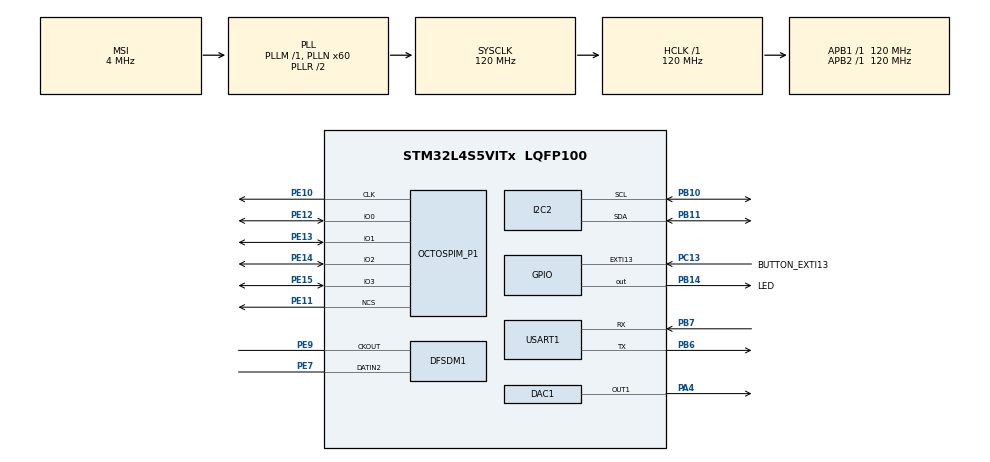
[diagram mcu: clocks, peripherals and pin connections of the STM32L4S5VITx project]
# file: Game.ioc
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DAC1.DAC_Trigger-DAC_OUT1=DAC_TRIGGER_T2_TRGO
DFSDM1.Divider=48
DFSDM1.DmaMode_reg_FIL0=ENABLE
DFSDM1.FastMode_reg_FIL0=ENABLE
DFSDM1.Filter_regChannel_FIL0=DFSDM_CHANNEL_2
DFSDM1.Fosr_FIL0=100
Dma.DAC1_CH1.0.Direction=DMA_MEMORY_TO_PERIPH
Dma.DAC1_CH1.0.EventEnable=DISABLE
Dma.DAC1_CH1.0.Instance=DMA1_Channel1
Dma.DAC1_CH1.0.MemDataAlignment=DMA_MDATAALIGN_WORD
Dma.DAC1_CH1.0.MemInc=DMA_MINC_ENABLE
Dma.DAC1_CH1.0.Mode=DMA_CIRCULAR
Dma.DAC1_CH1.0.PeriphDataAlignment=DMA_PDATAALIGN_WORD
Dma.DAC1_CH1.0.PeriphInc=DMA_PINC_DISABLE
Dma.DAC1_CH1.0.Polarity=HAL_DMAMUX_REQUEST_GEN_RISING
Dma.DAC1_CH1.0.Priority=DMA_PRIORITY_HIGH
Dma.DAC1_CH1.0.RequestNumber=1
Dma.DAC1_CH1.0.SignalID=NONE
Dma.DAC1_CH1.0.SyncEnable=DISABLE
Dma.DAC1_CH1.0.SyncPolarity=HAL_DMAMUX_SYNC_NO_EVENT
Dma.DAC1_CH1.0.SyncRequestNumber=1
Dma.DAC1_CH1.0.SyncSignalID=NONE
Dma.DFSDM1_FLT0.1.Direction=DMA_PERIPH_TO_MEMORY
Dma.DFSDM1_FLT0.1.EventEnable=DISABLE
Dma.DFSDM1_FLT0.1.Instance=DMA1_Channel2
Dma.DFSDM1_FLT0.1.MemDataAlignment=DMA_MDATAALIGN_WORD
Dma.DFSDM1_FLT0.1.MemInc=DMA_MINC_ENABLE
Dma.DFSDM1_FLT0.1.Mode=DMA_CIRCULAR
Dma.DFSDM1_FLT0.1.PeriphDataAlignment=DMA_PDATAALIGN_WORD
Dma.DFSDM1_FLT0.1.PeriphInc=DMA_PINC_DISABLE
Dma.DFSDM1_FLT0.1.Polarity=HAL_DMAMUX_REQUEST_GEN_RISING
Dma.DFSDM1_FLT0.1.Priority=DMA_PRIORITY_LOW
Dma.DFSDM1_FLT0.1.RequestNumber=1
Dma.DFSDM1_FLT0.1.SignalID=NONE
Dma.DFSDM1_FLT0.1.SyncEnable=DISABLE
Dma.DFSDM1_FLT0.1.SyncPolarity=HAL_DMAMUX_SYNC_NO_EVENT
Dma.DFSDM1_FLT0.1.SyncRequestNumber=1
Dma.DFSDM1_FLT0.1.SyncSignalID=NONE
Dma.Request0=DAC1_CH1
Dma.Request1=DFSDM1_FLT0
I2C2.Timing=0x30A175AB
Mcu.Family=STM32L4
Mcu.Name=STM32L4S5VITx
Mcu.Package=LQFP100
NVIC.DMA1_Channel1_IRQn=true\:0\:0\:false\:false\:true\:false\:true\:true
NVIC.DMA1_Channel2_IRQn=true\:0\:0\:false\:false\:true\:false\:true\:true
NVIC.EXTI15_10_IRQn=true\:0\:0\:false\:false\:true\:true\:true\:true
NVIC.PriorityGroup=NVIC_PRIORITYGROUP_4
NVIC.TIM2_IRQn=true\:0\:0\:false\:false\:true\:true\:true\:true
PA4.Signal=COMP_DAC11_group
PB10.Mode=I2C
PB10.Signal=I2C2_SCL
PB11.Mode=I2C
PB11.Signal=I2C2_SDA
PB14.GPIO_Label=LED
PB14.Signal=GPIO_Output
PB6.Mode=Asynchronous
PB6.Signal=USART1_TX
PB7.Mode=Asynchronous
PB7.Signal=USART1_RX
PC13.GPIO_Label=BUTTON_EXTI13
PC13.Signal=GPXTI13
PE10.Mode=O1_P1_CLK
PE10.Signal=OCTOSPIM_P1_CLK
PE11.Mode=OCTOSPI1_Port1_NCS
PE11.Signal=OCTOSPIM_P1_NCS
PE12.Mode=OCTOSPI1_IOL_Port1L
PE12.Signal=OCTOSPIM_P1_IO0
PE13.Mode=OCTOSPI1_IOL_Port1L
PE13.Signal=OCTOSPIM_P1_IO1
PE14.Mode=OCTOSPI1_IOL_Port1L
PE14.Signal=OCTOSPIM_P1_IO2
PE15.Mode=OCTOSPI1_IOL_Port1L
PE15.Signal=OCTOSPIM_P1_IO3
PE7.Signal=S_DATAIN2DFSDM1
PE9.Signal=S_CKOUTDFSDM1
ProjectManager.HeapSize=0x200
ProjectManager.StackSize=0x400
ProjectManager.TargetToolchain=STM32CubeIDE
RCC.ADCFreq_Value=48000000
RCC.AHBFreq_Value=120000000
RCC.APB1Freq_Value=120000000
RCC.APB1TimFreq_Value=120000000
RCC.APB2Freq_Value=120000000
RCC.APB2TimFreq_Value=120000000
RCC.CortexFreq_Value=120000000
RCC.HCLKFreq_Value=120000000
RCC.HSE_VALUE=8000000
RCC.HSI48_VALUE=48000000
RCC.HSI_VALUE=16000000
RCC.LSE_VALUE=32768
RCC.MSI_VALUE=4000000
RCC.PLLN=60
RCC.PLLSAI1N=24
RCC.SYSCLKFreq_VALUE=120000000
RCC.SYSCLKSource=RCC_SYSCLKSOURCE_PLLCLK
RCC.USBFreq_Value=48000000
RCC.VCOOutputFreq_Value=240000000
SH.COMP_DAC11_group.0=DAC1_OUT1,DAC_OUT1
SH.S_CKOUTDFSDM1.0=DFSDM1_CKOUT,CKOUT
SH.S_CKOUTDFSDM1.1=DFSDM1_CKOUT,PDM_SPI_input_from_ch2_and_internal_clock
SH.S_DATAIN2DFSDM1.0=DFSDM1_DATIN2,PDM_SPI_input_from_ch2_and_internal_clock
TIM2.Period=4800
TIM2.TIM_MasterOutputTrigger=TIM_TRGO_UPDATE
USART1.VirtualMode-Asynchronous=VM_ASYNC
VP_OCTOSPI1_VS_quad.Mode=quad_mode
VP_TIM2_VS_ClockSourceINT.Mode=Internal
board=B-L4S5I-IOT01A

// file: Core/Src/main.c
/* USER CODE BEGIN Header */
/**
  ******************************************************************************
  * @file           : main.c
  * @brief          : Main program body
  ******************************************************************************
  * @attention
  *
  * Copyright (c) 2025 STMicroelectronics.
  * All rights reserved.
  *
  * This software is licensed under terms that can be found in the LICENSE file
  * in the root directory of this software component.
  * If no LICENSE file comes with this software, it is provided AS-IS.
  *
  ******************************************************************************
  */
/* USER CODE END Header */
#include "main.h"

/* USER CODE BEGIN Includes */
#include "stm32l4s5i_iot01_qspi.h"
#include "app.h"
#include "audio_player.h"
/* USER CODE END Includes */

DAC_HandleTypeDef hdac1;
DMA_HandleTypeDef hdma_dac1_ch1;

DFSDM_Filter_HandleTypeDef hdfsdm1_filter0;
DFSDM_Channel_HandleTypeDef hdfsdm1_channel2;
DMA_HandleTypeDef hdma_dfsdm1_flt0;

I2C_HandleTypeDef hi2c2;

OSPI_HandleTypeDef hospi1;

TIM_HandleTypeDef htim2;

UART_HandleTypeDef huart1;

void SystemClock_Config(void);
static void MX_GPIO_Init(void);
static void MX_DMA_Init(void);
static void MX_DFSDM1_Init(void);
static void MX_USART1_UART_Init(void);
static void MX_I2C2_Init(void);
static void MX_OCTOSPI1_Init(void);
static void MX_TIM2_Init(void);
static void MX_DAC1_Init(void);

int main(void)
{

  /* MCU Configuration--------------------------------------------------------*/

  /* Reset of all peripherals, Initializes the Flash interface and the Systick. */
  HAL_Init();

  /* Configure the system clock */
  SystemClock_Config();

  /* Initialize all configured peripherals */
  MX_GPIO_Init();
  MX_DMA_Init();
  MX_DFSDM1_Init();
  MX_USART1_UART_Init();
  MX_I2C2_Init();
  MX_OCTOSPI1_Init();
  MX_TIM2_Init();
  MX_DAC1_Init();
  /* USER CODE BEGIN 2 */
  BOPIT_Set_I2C_Handle(&hi2c2);
  BOPIT_Set_UART_Handle(&huart1);
  if(BSP_QSPI_Init() != QSPI_OK){
	  Error_Handler();
  }
  HAL_TIM_Base_Start_IT(&htim2);
  AP_Init(&hdac1, &hdfsdm1_filter0);
  BOPIT_Start();

  /* USER CODE END 2 */

  /* Infinite loop */
  while (1)
  {

  }
}

void SystemClock_Config(void)
{
  RCC_OscInitTypeDef RCC_OscInitStruct = {0};
  RCC_ClkInitTypeDef RCC_ClkInitStruct = {0};

  /** Configure the main internal regulator output voltage
  */
  if (HAL_PWREx_ControlVoltageScaling(PWR_REGULATOR_VOLTAGE_SCALE1_BOOST) != HAL_OK)
  {
    Error_Handler();
  }

  /** Initializes the RCC Oscillators according to the specified parameters
  * in the RCC_OscInitTypeDef structure.
  */
  RCC_OscInitStruct.OscillatorType = RCC_OSCILLATORTYPE_MSI;
  RCC_OscInitStruct.MSIState = RCC_MSI_ON;
  RCC_OscInitStruct.MSICalibrationValue = 0;
  RCC_OscInitStruct.MSIClockRange = RCC_MSIRANGE_6;
  RCC_OscInitStruct.PLL.PLLState = RCC_PLL_ON;
  RCC_OscInitStruct.PLL.PLLSource = RCC_PLLSOURCE_MSI;
  RCC_OscInitStruct.PLL.PLLM = 1;
  RCC_OscInitStruct.PLL.PLLN = 60;
  RCC_OscInitStruct.PLL.PLLP = RCC_PLLP_DIV2;
  RCC_OscInitStruct.PLL.PLLQ = RCC_PLLQ_DIV2;
  RCC_OscInitStruct.PLL.PLLR = RCC_PLLR_DIV2;
  if (HAL_RCC_OscConfig(&RCC_OscInitStruct) != HAL_OK)
  {
    Error_Handler();
  }

  /** Initializes the CPU, AHB and APB buses clocks
  */
  RCC_ClkInitStruct.ClockType = RCC_CLOCKTYPE_HCLK|RCC_CLOCKTYPE_SYSCLK
                              |RCC_CLOCKTYPE_PCLK1|RCC_CLOCKTYPE_PCLK2;
  RCC_ClkInitStruct.SYSCLKSource = RCC_SYSCLKSOURCE_PLLCLK;
  RCC_ClkInitStruct.AHBCLKDivider = RCC_SYSCLK_DIV1;
  RCC_ClkInitStruct.APB1CLKDivider = RCC_HCLK_DIV1;
  RCC_ClkInitStruct.APB2CLKDivider = RCC_HCLK_DIV1;

  if (HAL_RCC_ClockConfig(&RCC_ClkInitStruct, FLASH_LATENCY_5) != HAL_OK)
  {
    Error_Handler();
  }
}

static void MX_DAC1_Init(void)
{

  DAC_ChannelConfTypeDef sConfig = {0};

  /** DAC Initialization
  */
  hdac1.Instance = DAC1;
  if (HAL_DAC_Init(&hdac1) != HAL_OK)
  {
    Error_Handler();
  }

  /** DAC channel OUT1 config
  */
  sConfig.DAC_SampleAndHold = DAC_SAMPLEANDHOLD_DISABLE;
  sConfig.DAC_Trigger = DAC_TRIGGER_T2_TRGO;
  sConfig.DAC_HighFrequency = DAC_HIGH_FREQUENCY_INTERFACE_MODE_ABOVE_80MHZ;
  sConfig.DAC_OutputBuffer = DAC_OUTPUTBUFFER_ENABLE;
  sConfig.DAC_ConnectOnChipPeripheral = DAC_CHIPCONNECT_DISABLE;
  sConfig.DAC_UserTrimming = DAC_TRIMMING_FACTORY;
  if (HAL_DAC_ConfigChannel(&hdac1, &sConfig, DAC_CHANNEL_1) != HAL_OK)
  {
    Error_Handler();
  }

}

static void MX_DFSDM1_Init(void)
{

  hdfsdm1_filter0.Instance = DFSDM1_Filter0;
  hdfsdm1_filter0.Init.RegularParam.Trigger = DFSDM_FILTER_SW_TRIGGER;
  hdfsdm1_filter0.Init.RegularParam.FastMode = ENABLE;
  hdfsdm1_filter0.Init.RegularParam.DmaMode = ENABLE;
  hdfsdm1_filter0.Init.FilterParam.SincOrder = DFSDM_FILTER_FASTSINC_ORDER;
  hdfsdm1_filter0.Init.FilterParam.Oversampling = 100;
  hdfsdm1_filter0.Init.FilterParam.IntOversampling = 1;
  if (HAL_DFSDM_FilterInit(&hdfsdm1_filter0) != HAL_OK)
  {
    Error_Handler();
  }
  hdfsdm1_channel2.Instance = DFSDM1_Channel2;
  hdfsdm1_channel2.Init.OutputClock.Activation = ENABLE;
  hdfsdm1_channel2.Init.OutputClock.Selection = DFSDM_CHANNEL_OUTPUT_CLOCK_SYSTEM;
  hdfsdm1_channel2.Init.OutputClock.Divider = 48;
  hdfsdm1_channel2.Init.Input.Multiplexer = DFSDM_CHANNEL_EXTERNAL_INPUTS;
  hdfsdm1_channel2.Init.Input.DataPacking = DFSDM_CHANNEL_STANDARD_MODE;
  hdfsdm1_channel2.Init.Input.Pins = DFSDM_CHANNEL_SAME_CHANNEL_PINS;
  hdfsdm1_channel2.Init.SerialInterface.Type = DFSDM_CHANNEL_SPI_RISING;
  hdfsdm1_channel2.Init.SerialInterface.SpiClock = DFSDM_CHANNEL_SPI_CLOCK_INTERNAL;
  hdfsdm1_channel2.Init.Awd.FilterOrder = DFSDM_CHANNEL_FASTSINC_ORDER;
  hdfsdm1_channel2.Init.Awd.Oversampling = 1;
  hdfsdm1_channel2.Init.Offset = 0;
  hdfsdm1_channel2.Init.RightBitShift = 0x00;
  if (HAL_DFSDM_ChannelInit(&hdfsdm1_channel2) != HAL_OK)
  {
    Error_Handler();
  }
  if (HAL_DFSDM_FilterConfigRegChannel(&hdfsdm1_filter0, DFSDM_CHANNEL_2, DFSDM_CONTINUOUS_CONV_ON) != HAL_OK)
  {
    Error_Handler();
  }

}

static void MX_I2C2_Init(void)
{

  hi2c2.Instance = I2C2;
  hi2c2.Init.Timing = 0x30A175AB;
  hi2c2.Init.OwnAddress1 = 0;
  hi2c2.Init.AddressingMode = I2C_ADDRESSINGMODE_7BIT;
  hi2c2.Init.DualAddressMode = I2C_DUALADDRESS_DISABLE;
  hi2c2.Init.OwnAddress2 = 0;
  hi2c2.Init.OwnAddress2Masks = I2C_OA2_NOMASK;
  hi2c2.Init.GeneralCallMode = I2C_GENERALCALL_DISABLE;
  hi2c2.Init.NoStretchMode = I2C_NOSTRETCH_DISABLE;
  if (HAL_I2C_Init(&hi2c2) != HAL_OK)
  {
    Error_Handler();
  }

  /** Configure Analogue filter
  */
  if (HAL_I2CEx_ConfigAnalogFilter(&hi2c2, I2C_ANALOGFILTER_ENABLE) != HAL_OK)
  {
    Error_Handler();
  }

  /** Configure Digital filter
  */
  if (HAL_I2CEx_ConfigDigitalFilter(&hi2c2, 0) != HAL_OK)
  {
    Error_Handler();
  }

}

static void MX_OCTOSPI1_Init(void)
{

  OSPIM_CfgTypeDef OSPIM_Cfg_Struct = {0};

  /* OCTOSPI1 parameter configuration*/
  hospi1.Instance = OCTOSPI1;
  hospi1.Init.FifoThreshold = 1;
  hospi1.Init.DualQuad = HAL_OSPI_DUALQUAD_DISABLE;
  hospi1.Init.MemoryType = HAL_OSPI_MEMTYPE_MICRON;
  hospi1.Init.DeviceSize = 32;
  hospi1.Init.ChipSelectHighTime = 1;
  hospi1.Init.FreeRunningClock = HAL_OSPI_FREERUNCLK_DISABLE;
  hospi1.Init.ClockMode = HAL_OSPI_CLOCK_MODE_0;
  hospi1.Init.ClockPrescaler = 1;
  hospi1.Init.SampleShifting = HAL_OSPI_SAMPLE_SHIFTING_NONE;
  hospi1.Init.DelayHoldQuarterCycle = HAL_OSPI_DHQC_DISABLE;
  hospi1.Init.ChipSelectBoundary = 0;
  hospi1.Init.DelayBlockBypass = HAL_OSPI_DELAY_BLOCK_BYPASSED;
  if (HAL_OSPI_Init(&hospi1) != HAL_OK)
  {
    Error_Handler();
  }
  OSPIM_Cfg_Struct.ClkPort = 1;
  OSPIM_Cfg_Struct.NCSPort = 1;
  OSPIM_Cfg_Struct.IOLowPort = HAL_OSPIM_IOPORT_1_LOW;
  if (HAL_OSPIM_Config(&hospi1, &OSPIM_Cfg_Struct, HAL_OSPI_TIMEOUT_DEFAULT_VALUE) != HAL_OK)
  {
    Error_Handler();
  }

}

static void MX_TIM2_Init(void)
{

  TIM_ClockConfigTypeDef sClockSourceConfig = {0};
  TIM_MasterConfigTypeDef sMasterConfig = {0};

  htim2.Instance = TIM2;
  htim2.Init.Prescaler = 0;
  htim2.Init.CounterMode = TIM_COUNTERMODE_UP;
  htim2.Init.Period = 4800;
  htim2.Init.ClockDivision = TIM_CLOCKDIVISION_DIV1;
  htim2.Init.AutoReloadPreload = TIM_AUTORELOAD_PRELOAD_DISABLE;
  if (HAL_TIM_Base_Init(&htim2) != HAL_OK)
  {
    Error_Handler();
  }
  sClockSourceConfig.ClockSource = TIM_CLOCKSOURCE_INTERNAL;
  if (HAL_TIM_ConfigClockSource(&htim2, &sClockSourceConfig) != HAL_OK)
  {
    Error_Handler();
  }
  sMasterConfig.MasterOutputTrigger = TIM_TRGO_UPDATE;
  sMasterConfig.MasterSlaveMode = TIM_MASTERSLAVEMODE_DISABLE;
  if (HAL_TIMEx_MasterConfigSynchronization(&htim2, &sMasterConfig) != HAL_OK)
  {
    Error_Handler();
  }

}

static void MX_USART1_UART_Init(void)
{

  huart1.Instance = USART1;
  huart1.Init.BaudRate = 115200;
  huart1.Init.WordLength = UART_WORDLENGTH_8B;
  huart1.Init.StopBits = UART_STOPBITS_1;
  huart1.Init.Parity = UART_PARITY_NONE;
  huart1.Init.Mode = UART_MODE_TX_RX;
  huart1.Init.HwFlowCtl = UART_HWCONTROL_NONE;
  huart1.Init.OverSampling = UART_OVERSAMPLING_16;
  huart1.Init.OneBitSampling = UART_ONE_BIT_SAMPLE_DISABLE;
  huart1.Init.ClockPrescaler = UART_PRESCALER_DIV1;
  huart1.AdvancedInit.AdvFeatureInit = UART_ADVFEATURE_NO_INIT;
  if (HAL_UART_Init(&huart1) != HAL_OK)
  {
    Error_Handler();
  }
  if (HAL_UARTEx_SetTxFifoThreshold(&huart1, UART_TXFIFO_THRESHOLD_1_8) != HAL_OK)
  {
    Error_Handler();
  }
  if (HAL_UARTEx_SetRxFifoThreshold(&huart1, UART_RXFIFO_THRESHOLD_1_8) != HAL_OK)
  {
    Error_Handler();
  }
  if (HAL_UARTEx_DisableFifoMode(&huart1) != HAL_OK)
  {
    Error_Handler();
  }

}

static void MX_DMA_Init(void)
{

  /* DMA controller clock enable */
  __HAL_RCC_DMAMUX1_CLK_ENABLE();
  __HAL_RCC_DMA1_CLK_ENABLE();

  /* DMA interrupt init */
  /* DMA1_Channel1_IRQn interrupt configuration */
  HAL_NVIC_SetPriority(DMA1_Channel1_IRQn, 0, 0);
  HAL_NVIC_EnableIRQ(DMA1_Channel1_IRQn);
  /* DMA1_Channel2_IRQn interrupt configuration */
  HAL_NVIC_SetPriority(DMA1_Channel2_IRQn, 0, 0);
  HAL_NVIC_EnableIRQ(DMA1_Channel2_IRQn);

}

static void MX_GPIO_Init(void)
{
  GPIO_InitTypeDef GPIO_InitStruct = {0};

  /* GPIO Ports Clock Enable */
  __HAL_RCC_GPIOC_CLK_ENABLE();
  __HAL_RCC_GPIOA_CLK_ENABLE();
  __HAL_RCC_GPIOE_CLK_ENABLE();
  __HAL_RCC_GPIOB_CLK_ENABLE();

  /*Configure GPIO pin Output Level */
  HAL_GPIO_WritePin(LED_GPIO_Port, LED_Pin, GPIO_PIN_RESET);

  /*Configure GPIO pin : BUTTON_EXTI13_Pin */
  GPIO_InitStruct.Pin = BUTTON_EXTI13_Pin;
  GPIO_InitStruct.Mode = GPIO_MODE_IT_RISING;
  GPIO_InitStruct.Pull = GPIO_NOPULL;
  HAL_GPIO_Init(BUTTON_EXTI13_GPIO_Port, &GPIO_InitStruct);

  /*Configure GPIO pin : LED_Pin */
  GPIO_InitStruct.Pin = LED_Pin;
  GPIO_InitStruct.Mode = GPIO_MODE_OUTPUT_PP;
  GPIO_InitStruct.Pull = GPIO_NOPULL;
  GPIO_InitStruct.Speed = GPIO_SPEED_FREQ_LOW;
  HAL_GPIO_Init(LED_GPIO_Port, &GPIO_InitStruct);

  /* EXTI interrupt init*/
  HAL_NVIC_SetPriority(EXTI15_10_IRQn, 0, 0);
  HAL_NVIC_EnableIRQ(EXTI15_10_IRQn);

}

/* USER CODE BEGIN 4 */

void HAL_GPIO_EXTI_Callback(uint16_t pin) {
  if (pin == BUTTON_EXTI13_Pin) {
    BOPIT_Handle_Button_Press();
  }
}

/* USER CODE END 4 */

void Error_Handler(void)
{
  __disable_irq();
  while (1)
  {
  }
}
